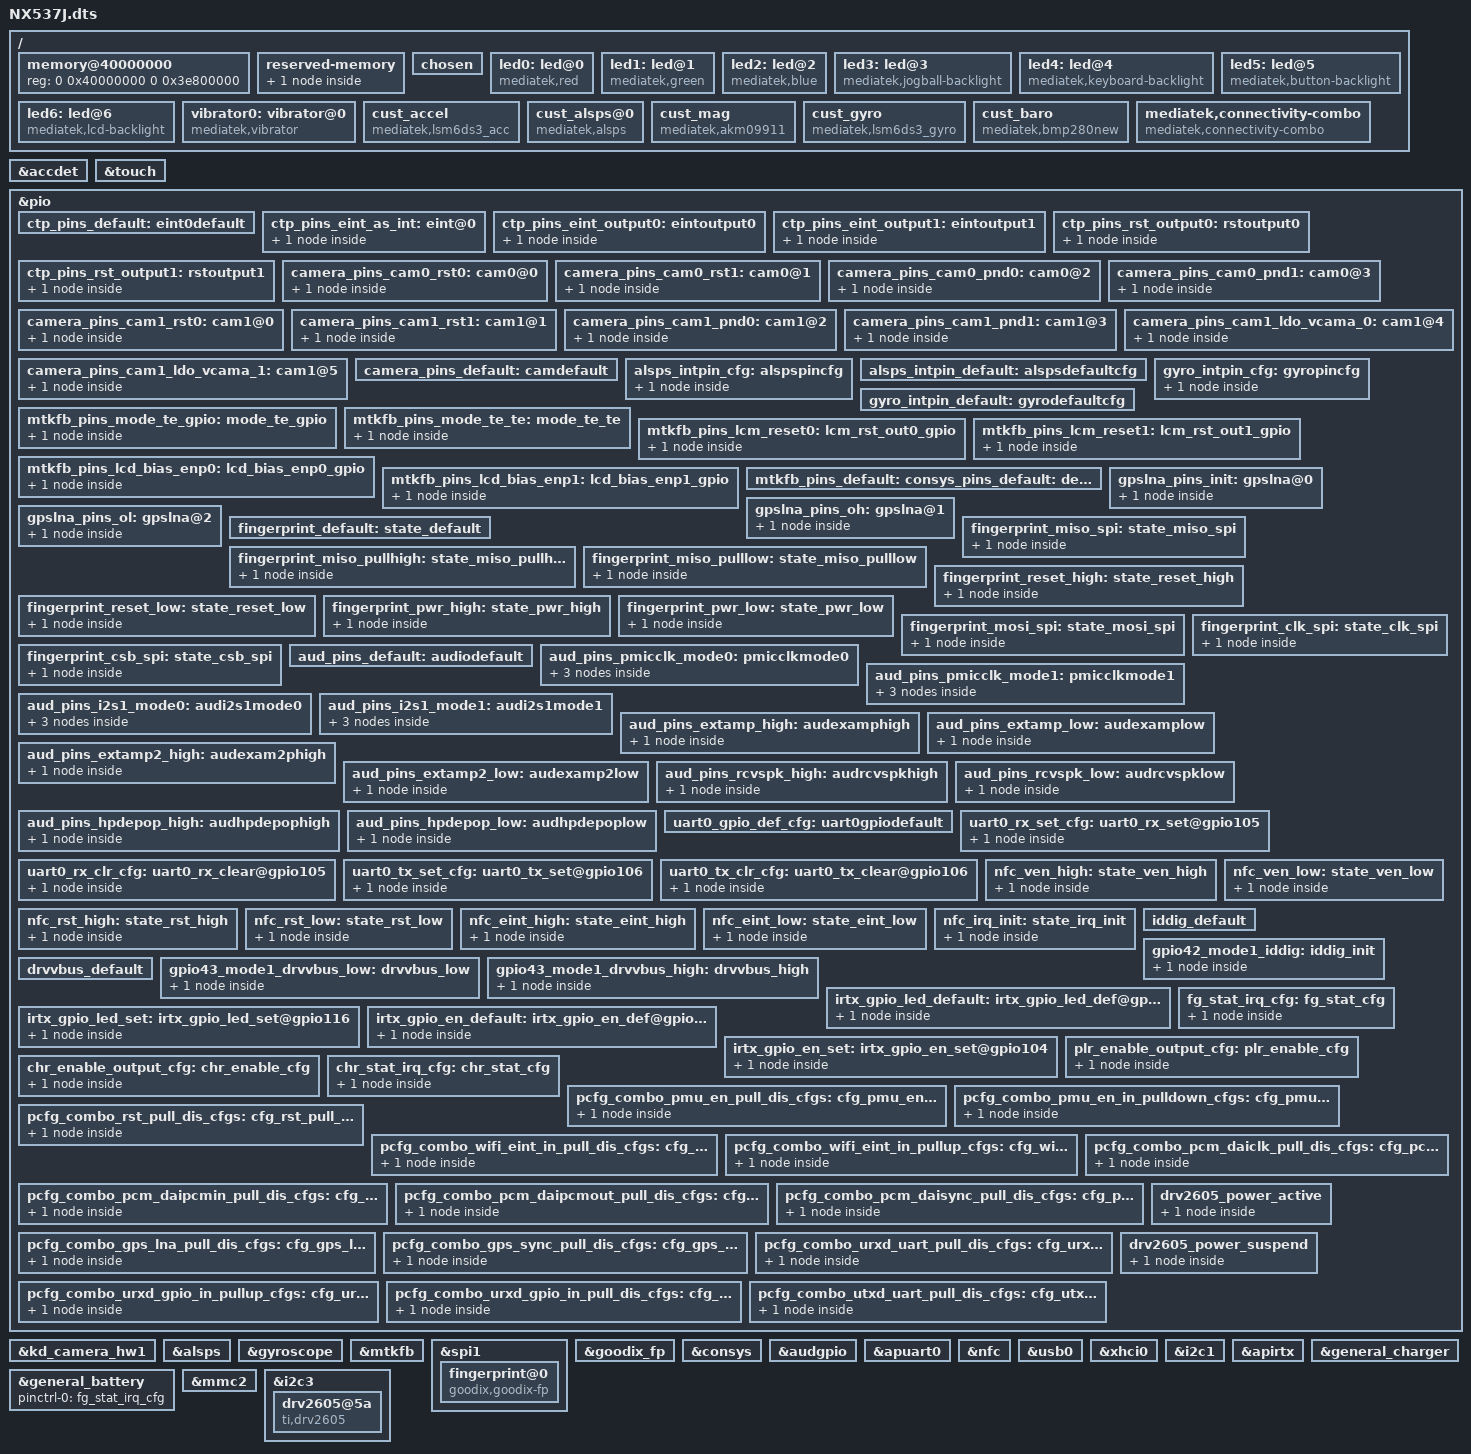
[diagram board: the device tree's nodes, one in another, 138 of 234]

/dts-v1/;

#include "mt6755_NX537J.dtsi"
#include "cust.dtsi"

/ {
	memory@40000000 {
		device_type = "memory";
		reg = <0 0x40000000 0 0x3e800000>;
	};
	reserved-memory {
		#address-cells = <2>;
		#size-cells = <2>;
		ranges;

		reserve-memory-ccci_md3_ccif {
			compatible = "mediatek,reserve-memory-ccci_md3_ccif";
			no-map;
			size = <0 0x01000000>;
			alignment = <0 0x2000000>;
			alloc-ranges = <0 0x40000000 0 0xc0000000>;
		};
	};

	/* chosen */
	chosen {
		bootargs = "console=tty0 console=ttyMT0,921600n1 root=/dev/ram initrd=0x44000000,0x4B434E loglevel=8";

		/* fpga may has no lk, we need to specify display info here */
		/* fb buffer is reserved using this dts by memory node above */
		atag,videolfb-fb_base_h = <0x0>;
		atag,videolfb-fb_base_l = <0x7E800000>;
		atag,videolfb-islcmfound = <1>;
		/* because no lk, so lcm is not inited */
		atag,videolfb-islcm_inited = <0>;
		atag,videolfb-fps= <6000>;
		atag,videolfb-vramSize= <0x01800000>;
		atag,videolfb-lcmname= "nt35695_fhd_dsi_cmd_truly_nt50358_drv";
	};
	led0:led@0 {
		compatible = "mediatek,red";
		led_mode = <0>;
		data = <1>;
		pwm_config = <0 0 0 0 0>;
	};
	led1:led@1 {
		compatible = "mediatek,green";
		led_mode = <0>;
		data = <1>;
		pwm_config = <0 0 0 0 0>;
	};
	led2:led@2 {
		compatible = "mediatek,blue";
		led_mode = <0>;
		data = <1>;
		pwm_config = <0 0 0 0 0>;
	};
	led3:led@3 {
		compatible = "mediatek,jogball-backlight";
		led_mode = <0>;
		data = <1>;
		pwm_config = <0 0 0 0 0>;
	};
	led4:led@4 {
		compatible = "mediatek,keyboard-backlight";
		led_mode = <0>;
		data = <1>;
		pwm_config = <0 0 0 0 0>;
	};
	led5:led@5 {
		compatible = "mediatek,button-backlight";
		led_mode = <0>;
		data = <1>;
		pwm_config = <0 0 0 0 0>;
	};
	led6:led@6 {
		compatible = "mediatek,lcd-backlight";
		led_mode = <4>;
		data = <1>;
		pwm_config = <0 0 0 0 0>;
	};
	vibrator0:vibrator@0 {
		compatible = "mediatek,vibrator";
		vib_timer = <25>;
		vib_limit = <9>;
		vib_vol= <5>;
	};
/*  start sensor */
	cust_accel {
		compatible = "mediatek,lsm6ds3_acc";
		i2c_num	= <1>;
		/* i2c_addr = <0x4c 0 0 0>; */
		direction = <0>;
		power_id = <0xffff>;
		power_vol = <0>;
		firlen = <16>;
		is_batch_supported = <1>;
	};

	cust_alsps@0 {
		compatible		= "mediatek,alsps";
		i2c_num			= <1>;
		i2c_addr		= <0x38 0 0 0>;
		polling_mode_ps		= <0>;
		polling_mode_als	= <1>;
		power_id		= <0xffff>;
		power_vol		= <0>;
/* Total has 15 level*/
		als_level	= <0 419 952 1557 3673 9092 9177 15211 26458 32570 38895 53287 65535 65535 65535>;
/*  Total has 16 range*/
		als_value	= <0 133 303 503 1003 2004 3008 5001 8009 10000 12000 16000 20000 20000 20000 20000>;
		ps_threshold_high	=  <32>;
		ps_threshold_low	=  <22>;
		is_batch_supported_ps	= <0>;
		is_batch_supported_als	= <0>;
	};

	cust_mag {
		compatible			= "mediatek,akm09911";
		i2c_num				= <1>;
		/* i2c_addr			= <0x0d 0 0 0>; */
		direction			= <1>;
		power_id			= <0xffff>;
		power_vol			= <0>;
		/* is_batch_supported		= <0>; */
	};

	cust_gyro {
		compatible			= "mediatek,lsm6ds3_gyro";
		i2c_num				= <1>;
		/* i2c_addr			= <0x68 0 0 0>; */
		direction			= <0>;
		power_id			= <0xffff>;
		power_vol			= <0>;
		firlen				= <0>;
		is_batch_supported		= <0>;
		addr                = <0x6b>;
	};

	cust_baro {
		compatible			= "mediatek,bmp280new";
		i2c_num				= <1>;
		/* i2c_addr			= <0x68 0 0 0>; */
		direction			= <0>;
		power_id			= <0xffff>;
		power_vol			= <0>;
		firlen				= <32>;
		is_batch_supported		= <0>;
	};
/* end sensor */

	mediatek,connectivity-combo {
		compatible = "mediatek,connectivity-combo";
		/*gpio_combo_ldo_en_pin = <&pio 0xffff 0>;	/*0) GPIO_COMBO_LDO_EN_PIN */
		/*gpio_combo_pmuv28_en_pin = <&pio 0xffff 0>;	/* 1) GPIO_COMBO_PMUV28_EN_PIN */
		gpio_combo_pmu_en_pin = <&pio 122 0>;		/* 2) GPIO_COMBO_PMU_EN_PIN */
		gpio_combo_rst_pin = <&pio 119 0>;		/* 3) GPIO_COMBO_RST_PIN pin */
		/*gpio_combo_bgf_eint_pin = <&pio 0xffff 0>;	/* 4) GPIO_COMBO_BGF_EINT_PIN */
		gpio_wifi_eint_pin = <&pio 120 0>;		/* 5) GPIO_WIFI_EINT_PIN */
		/*gpio_all_eint_pin = <&pio 0xffff 0>;		/* 6) GPIO_ALL_EINT_PIN */
		/*gpio_combo_urxd_pin = <&pio 0xffff 0>;		/* 7) GPIO_COMBO_URXD_PIN */
		/*gpio_combo_utxd_pin = <&pio 0xffff 0>;		/* 8) GPIO_COMBO_UTXD_PIN */
		gpio_pcm_daiclk_pin = <&pio 14 0>;		/* 9) GPIO_PCM_DAICLK_PIN */
		gpio_pcm_daipcmin_pin = <&pio 16 0>;		/* 10) GPIO_PCM_DAIPCMIN_PIN */
		gpio_pcm_daipcmout_pin = <&pio 15 0>;		/* 11) GPIO_PCM_DAIPCMOUT_PIN */
		gpio_pcm_daisync_pin = <&pio 13 0>;		/* 12) GPIO_PCM_DAISYNC_PIN */
		/*gpio_combo_i2s_ck_pin = <&pio 0xffff 0>;	/* 13) GPIO_COMBO_I2S_CK_PIN */
		/*gpio_combo_i2s_ws_pin = <&pio 0xffff 0>;	/* 14) GPIO_COMBO_I2S_WS_PIN */
		/*gpio_combo_i2s_dat_pin = <&pio 0xffff 0>;	/* 15) GPIO_COMBO_I2S_DAT_PIN */
		gpio_gps_sync_pin = <&pio 121 0>;		/* 16) GPIO_GPS_SYNC_PIN */
		gpio_gps_lna_pin = <&pio 114 0>;		/* 17) GPIO_GPS_LNA_PIN is ext pin on 6397 */
		gpio_combo_urxd_pin = <&pio 118 0>;
		gpio_combo_utxd_pin = <&pio 117 0>;
		pinctrl-names = "gpio_pmu_en_pull_dis",
			"gpio_pmu_en_in_pulldown",
			"gpio_rst_pull_dis",
			"gpio_wifi_eint_in_pull_dis",
			"gpio_wifi_eint_in_pullup",
			"gpio_pcm_daiclk_pull_dis",
			"gpio_pcm_daipcmin_pull_dis",
			"gpio_pcm_daipcmout_pull_dis",
			"gpio_pcm_daisync_pull_dis",
			"gpio_gps_lna_pull_dis",
			"gpio_gps_sync_pull_dis",
			"gpio_urxd_uart_pull_dis",
			"gpio_urxd_gpio_in_pullup",
			"gpio_urxd_gpio_in_pull_dis",
			"gpio_utxd_uart_pull_dis";
		pinctrl-0 = <&pcfg_combo_pmu_en_pull_dis_cfgs>;
		pinctrl-1 = <&pcfg_combo_pmu_en_in_pulldown_cfgs>;
		pinctrl-2 = <&pcfg_combo_rst_pull_dis_cfgs>;
		pinctrl-3 = <&pcfg_combo_wifi_eint_in_pull_dis_cfgs>;
		pinctrl-4 = <&pcfg_combo_wifi_eint_in_pullup_cfgs>;
		pinctrl-5 = <&pcfg_combo_pcm_daiclk_pull_dis_cfgs>;
		pinctrl-6 = <&pcfg_combo_pcm_daipcmin_pull_dis_cfgs>;
		pinctrl-7 = <&pcfg_combo_pcm_daipcmout_pull_dis_cfgs>;
		pinctrl-8 = <&pcfg_combo_pcm_daisync_pull_dis_cfgs>;
		pinctrl-9 = <&pcfg_combo_gps_lna_pull_dis_cfgs>;
		pinctrl-10 = <&pcfg_combo_gps_sync_pull_dis_cfgs>;
		pinctrl-11 = <&pcfg_combo_urxd_uart_pull_dis_cfgs>;
		pinctrl-12 = <&pcfg_combo_urxd_gpio_in_pullup_cfgs>;
		pinctrl-13 = <&pcfg_combo_urxd_gpio_in_pull_dis_cfgs>;
		pinctrl-14 = <&pcfg_combo_utxd_uart_pull_dis_cfgs>;
		interrupt-parent = <&eintc>;
		interrupts = < 120 IRQ_TYPE_LEVEL_LOW >;	/* WIFI EINT num is 1 active low level-sensitive */
		debounce = <18 0>;
		status = "okay";
	};
};
&accdet {
		accdet-mic-vol = <7>;
		headset-mode-setting = <0x500 0x500 1 0x3F0 0x800 0x800 0x200>;
		accdet-plugout-debounce = <20>;
		/*1:ACC mode, 2:low cost without in bias, 6:low cost with in bias*/
		accdet-mic-mode = <2>;
		/*0--MD_MAX--UP_MAX--DW_MAX*/
		headset-three-key-threshold = <0 80 220 500>;
		/*0--MD_MAX--VOICE_MAX--UP_MAX--DW_MAX*/
		headset-four-key-threshold = <0 58 121 192 450>;
};

/* TOUCH start */
&touch {
	tpd-resolution = <1080 1920>;
	use-tpd-button = <0>;
	tpd-key-num = <3>;
	tpd-key-local= <139 172 158 0>;
	tpd-key-dim-local = <90 883 100 40 230 883 100 40 370 883 100 40 0 0 0 0>;
	tpd-max-touch-num = <5>;
	tpd-filter-enable = <1>;
	tpd-filter-pixel-density = <146>;
	tpd-filter-custom-prameters = <0 0 0 0 0 0 0 0 0 0 0 0>;
	tpd-filter-custom-speed = <0 0 0>;
	pinctrl-names = "default", "state_eint_as_int", "state_eint_output0", "state_eint_output1",
		"state_rst_output0", "state_rst_output1";
	pinctrl-0 = <&ctp_pins_default>;
	pinctrl-1 = <&ctp_pins_eint_as_int>;
	pinctrl-2 = <&ctp_pins_eint_output0>;
	pinctrl-3 = <&ctp_pins_eint_output1>;
	pinctrl-4 = <&ctp_pins_rst_output0>;
	pinctrl-5 = <&ctp_pins_rst_output1>;
	status = "okay";
};
&pio {
	ctp_pins_default: eint0default {
	};
	ctp_pins_eint_as_int: eint@0 {
		pins_cmd_dat {
			pins = <PINMUX_GPIO5__FUNC_GPIO5>;
			slew-rate = <0>;
			bias-pull-up = <00>;
		};
	};
	ctp_pins_eint_output0: eintoutput0 {
		pins_cmd_dat {
			pins = <PINMUX_GPIO5__FUNC_GPIO5>;
			slew-rate = <1>;
			output-low;
		};
	};
	ctp_pins_eint_output1: eintoutput1 {
		pins_cmd_dat {
			pins = <PINMUX_GPIO5__FUNC_GPIO5>;
			slew-rate = <1>;
			output-high;
		};
	};
	ctp_pins_rst_output0: rstoutput0 {
		pins_cmd_dat {
			pins = <PINMUX_GPIO56__FUNC_GPIO56>;
			slew-rate = <1>;
			output-low;
		};
	};
	ctp_pins_rst_output1: rstoutput1 {
		pins_cmd_dat {
			pins = <PINMUX_GPIO56__FUNC_GPIO56>;
			slew-rate = <1>;
			output-high;
		};
	};
};
/* TOUCH end */

/* CAMERA GPIO standardization */
&pio {
	camera_pins_cam0_rst0: cam0@0 {
	    pins_cmd_dat {
			pins = <PINMUX_GPIO110__FUNC_GPIO110>;
			slew-rate = <1>; /*direction 0:in, 1:out*/
			output-low;/*direction out used only. output_low or high*/
		};
	};
	camera_pins_cam0_rst1: cam0@1 {
	    pins_cmd_dat {
			pins = <PINMUX_GPIO110__FUNC_GPIO110>;
			slew-rate = <1>;
			output-high;
		};
	};
	camera_pins_cam0_pnd0: cam0@2 {
	    pins_cmd_dat {
			pins = <PINMUX_GPIO107__FUNC_GPIO107>;
			slew-rate = <1>;
			output-low;
		};
	};
	camera_pins_cam0_pnd1: cam0@3 {
	    pins_cmd_dat {
			pins = <PINMUX_GPIO107__FUNC_GPIO107>;
			slew-rate = <1>;
			output-high;
		};
	};
	camera_pins_cam1_rst0: cam1@0 {
	    pins_cmd_dat {
			pins = <PINMUX_GPIO111__FUNC_GPIO111>;
			slew-rate = <1>; /*direction 0:in, 1:out*/
			output-low;/*direction out used only. output_low or high*/
		};
	};
	camera_pins_cam1_rst1: cam1@1 {
	    pins_cmd_dat {
			pins = <PINMUX_GPIO111__FUNC_GPIO111>;
			slew-rate = <1>;
			output-high;
		};
	};
	camera_pins_cam1_pnd0: cam1@2 {
	    pins_cmd_dat {
			pins = <PINMUX_GPIO108__FUNC_GPIO108>;
			slew-rate = <1>;
			output-low;
		};
	};
	camera_pins_cam1_pnd1: cam1@3 {
	    pins_cmd_dat {
			pins = <PINMUX_GPIO108__FUNC_GPIO108>;
			slew-rate = <1>;
			output-high;
		};
	};
	camera_pins_cam1_ldo_vcama_0: cam1@4 {
		       pins_cmd_dat {
			pins = <PINMUX_GPIO24__FUNC_GPIO24>;
			slew-rate = <1>;
			output-low;
		};
	};
	camera_pins_cam1_ldo_vcama_1: cam1@5 {
		    pins_cmd_dat {
			pins = <PINMUX_GPIO24__FUNC_GPIO24>;
			slew-rate = <1>;
			output-high;
		};
	};
	camera_pins_default: camdefault {
	};

};

&kd_camera_hw1 {
	pinctrl-names = "default",
			"cam0_rst0", "cam0_rst1", "cam0_pnd0", "cam0_pnd1",
			"cam1_rst0", "cam1_rst1", "cam1_pnd0", "cam1_pnd1",
			/*"cam2_rst0", "cam2_rst1", "cam2_pnd0", "cam2_pnd1",*/
			"cam1_ldo_vcama_0", "cam1_ldo_vcama_1";
	pinctrl-0 = <&camera_pins_default>;
	pinctrl-1 = <&camera_pins_cam0_rst0>;
	pinctrl-2 = <&camera_pins_cam0_rst1>;
	pinctrl-3 = <&camera_pins_cam0_pnd0>;
	pinctrl-4 = <&camera_pins_cam0_pnd1>;
	pinctrl-5 = <&camera_pins_cam1_rst0>;
	pinctrl-6 = <&camera_pins_cam1_rst1>;
	pinctrl-7 = <&camera_pins_cam1_pnd0>;
	pinctrl-8 = <&camera_pins_cam1_pnd1>;
	/* for main2 */
	/*pinctrl-9 = <&camera_pins_cam2_rst0>;
	pinctrl-10 = <&camera_pins_cam2_rst1>;
	pinctrl-11 = <&camera_pins_cam2_pnd0>;
	pinctrl-12 = <&camera_pins_cam2_pnd1>;*/
	/* for ldo control by gpio */
	pinctrl-9 = <&camera_pins_cam1_ldo_vcama_0>;
	pinctrl-10 = <&camera_pins_cam1_ldo_vcama_1>;
	status = "okay";

};
/* CAMERA GPIO end */

&pio {
	alsps_intpin_cfg: alspspincfg {

		pins_cmd_dat {
			pins = <PINMUX_GPIO12__FUNC_GPIO12>;
			slew-rate = <0>;
			bias-pull-up = <00>;
		};
	};

	alsps_intpin_default: alspsdefaultcfg {

	};

	gyro_intpin_cfg: gyropincfg {

		pins_cmd_dat {
			pins = <PINMUX_GPIO4__FUNC_GPIO4>;
			slew-rate = <0>;
			bias-pull-down = <00>;
		};
	};

	gyro_intpin_default: gyrodefaultcfg {

	};
};

&alsps {
	pinctrl-names = "pin_default", "pin_cfg";
	pinctrl-0 = <&alsps_intpin_default>;
	pinctrl-1 = <&alsps_intpin_cfg>;
	status = "okay";
};

&gyroscope {
	pinctrl-names = "pin_default", "pin_cfg";
	pinctrl-0 = <&gyro_intpin_default>;
	pinctrl-1 = <&gyro_intpin_cfg>;
	status = "okay";
};

/* DISPSYS GPIO standardization */
&pio {

	mtkfb_pins_mode_te_gpio: mode_te_gpio {
		pins_cmd_dat {
			pins = <PINMUX_GPIO44__FUNC_GPIO44>;
		};
	};

	mtkfb_pins_mode_te_te: mode_te_te {
		pins_cmd_dat {
			pins = <PINMUX_GPIO44__FUNC_DSI_TE>;
		};
	};

	mtkfb_pins_lcm_reset0: lcm_rst_out0_gpio {
		pins_cmd_dat {
			pins = <PINMUX_GPIO158__FUNC_LCM_RST>;
			slew-rate = <1>;
			output-low;
		};
	};

	mtkfb_pins_lcm_reset1: lcm_rst_out1_gpio {
		pins_cmd_dat {
			pins = <PINMUX_GPIO158__FUNC_LCM_RST>;
			slew-rate = <1>;
			output-high;
		};
	};

	mtkfb_pins_lcd_bias_enp0: lcd_bias_enp0_gpio {
		pins_cmd_dat {
			pins = <PINMUX_GPIO12__FUNC_GPIO12>;
			slew-rate = <1>;
			output-low;
		};
	};

	mtkfb_pins_lcd_bias_enp1: lcd_bias_enp1_gpio {
		pins_cmd_dat {
			pins = <PINMUX_GPIO12__FUNC_GPIO12>;
			slew-rate = <1>;
			output-high;
		};
	};

	mtkfb_pins_default: default {
	};
};

&mtkfb {
	pinctrl-names = "default", "mode_te_gpio", "mode_te_te", "lcm_rst_out0_gpio",
	"lcm_rst_out1_gpio", "lcd_bias_enp0_gpio", "lcd_bias_enp1_gpio";
	pinctrl-0 = <&mtkfb_pins_default>;
	pinctrl-1 = <&mtkfb_pins_mode_te_gpio>;
	pinctrl-2 = <&mtkfb_pins_mode_te_te>;
	pinctrl-3 = <&mtkfb_pins_lcm_reset0>;
	pinctrl-4 = <&mtkfb_pins_lcm_reset1>;
	pinctrl-5 = <&mtkfb_pins_lcd_bias_enp0>;
	pinctrl-6 = <&mtkfb_pins_lcd_bias_enp1>;
	status = "okay";
};/* DISPSYS GPIO standardization end */

/* CONSYS GPIO standardization */
&pio {
	consys_pins_default: default {
	};

	gpslna_pins_init: gpslna@0 {
		pins_cmd_dat {
			pins = <PINMUX_GPIO114__FUNC_GPIO114>;
			slew-rate = <0>;
			bias-disable;
			output-low;
		};
	};

	gpslna_pins_oh: gpslna@1 {
		pins_cmd_dat {
			pins = <PINMUX_GPIO114__FUNC_GPIO114>;
			slew-rate = <1>;
			output-high;
		};
	};

	gpslna_pins_ol: gpslna@2 {
		pins_cmd_dat {
			pins = <PINMUX_GPIO114__FUNC_GPIO114>;
			slew-rate = <1>;
			output-low;
		};
	};
};

/* FINGERPRINT start */
&spi1 {
	#address-cells = <1>;
	#size-cells = <0>;

	fingerprint@0 {
		compatible = "goodix,goodix-fp";
		reg = <0>;
		spi-max-frequency = <8000000>;
		status = "okay";
	};
};

&goodix_fp {
	pinctrl-names = "default", "miso_spi", "miso_pullhigh", "miso_pulllow", "reset_high", "reset_low", "pwr_high", "pwr_low", "mosi_spi", "clk_spi", "csb_spi";
	pinctrl-0 = <&fingerprint_default>;
	pinctrl-1 = <&fingerprint_miso_spi>;
	pinctrl-2 = <&fingerprint_miso_pullhigh>;
	pinctrl-3 = <&fingerprint_miso_pulllow>;
	pinctrl-4 = <&fingerprint_reset_high>;
	pinctrl-5 = <&fingerprint_reset_low>;
	pinctrl-6 = <&fingerprint_pwr_high>;
	pinctrl-7 = <&fingerprint_pwr_low>;
	pinctrl-8 = <&fingerprint_mosi_spi>;
	pinctrl-9 = <&fingerprint_clk_spi>;
	pinctrl-10 = <&fingerprint_csb_spi>;

	status = "okay";
};
&pio {
	fingerprint_default: state_default {

	};

	fingerprint_miso_spi: state_miso_spi {
		pins_cmd_dat {
			pins = <PINMUX_GPIO25__FUNC_SPI1_A_MI>;
		};
	};

	fingerprint_miso_pullhigh: state_miso_pullhigh {
		pins_cmd_dat {
			pins = <PINMUX_GPIO25__FUNC_GPIO25>;
			slew-rate = <1>;
			output-high;
		};
	};
	fingerprint_miso_pulllow: state_miso_pulllow {
		pins_cmd_dat {
			pins = <PINMUX_GPIO25__FUNC_GPIO25>;
			slew-rate = <1>;
			output-low;
		};
	};

	fingerprint_reset_high: state_reset_high {
		pins_cmd_dat {
			pins = <PINMUX_GPIO61__FUNC_GPIO61>;
			slew-rate = <1>;
			output-high;
		};
	};

	fingerprint_reset_low: state_reset_low {
		pins_cmd_dat {
			pins = <PINMUX_GPIO61__FUNC_GPIO61>;
			slew-rate = <1>;
			output-low;
		};
	};

	fingerprint_pwr_high: state_pwr_high {
		pins_cmd_dat {
			pins = <PINMUX_GPIO60__FUNC_GPIO60>;
			slew-rate = <1>;
			output-high;
		};
	};

	fingerprint_pwr_low: state_pwr_low {
		pins_cmd_dat {
			pins = <PINMUX_GPIO60__FUNC_GPIO60>;
			slew-rate = <1>;
			output-low;
		};
	};

	fingerprint_mosi_spi: state_mosi_spi {
		pins_cmd_dat {
			pins = <PINMUX_GPIO27__FUNC_SPI1_A_MO>;
		};
	};

	fingerprint_clk_spi: state_clk_spi {
		pins_cmd_dat {
			pins = <PINMUX_GPIO28__FUNC_SPI1_A_CLK>;
		};
	};

	fingerprint_csb_spi: state_csb_spi {
		pins_cmd_dat {
			pins = <PINMUX_GPIO26__FUNC_SPI1_A_CSB>;
		};
	};
};
/* FINGERPRINT end */
&consys {
	pinctrl-names = "default", "gps_lna_state_init", "gps_lna_state_oh", "gps_lna_state_ol";
	pinctrl-0 = <&consys_pins_default>;
	pinctrl-1 = <&gpslna_pins_init>;
	pinctrl-2 = <&gpslna_pins_oh>;
	pinctrl-3 = <&gpslna_pins_ol>;
	status = "okay";
};
/* CONSYS end */

/* AUDIO GPIO standardization */
&audgpio {
	pinctrl-names = "default", "audpmicclk-mode0", "audpmicclk-mode1",
		"audi2s1-mode0", "audi2s1-mode1", "extamp-pullhigh", "extamp-pulllow",
		"extamp2-pullhigh", "extamp2-pulllow", "rcvspk-pullhigh",
		"rcvspk-pulllow","hpdepop-pullhigh","hpdepop-pulllow";
	pinctrl-0 = <&aud_pins_default>;
	pinctrl-1 = <&aud_pins_pmicclk_mode0>;
	pinctrl-2 = <&aud_pins_pmicclk_mode1>;
	pinctrl-3 = <&aud_pins_i2s1_mode0>;
	pinctrl-4 = <&aud_pins_i2s1_mode1>;
	pinctrl-5 = <&aud_pins_default>;
	pinctrl-6 = <&aud_pins_default>;
	pinctrl-7 = <&aud_pins_extamp2_high>;
	pinctrl-8 = <&aud_pins_extamp2_low>;
	pinctrl-9 = <&aud_pins_rcvspk_high>;
	pinctrl-10 = <&aud_pins_rcvspk_low>;
	pinctrl-11 = <&aud_pins_hpdepop_high>;
	pinctrl-12 = <&aud_pins_hpdepop_low>;
	status = "okay";
};

&pio {
	aud_pins_default: audiodefault {
	};

	aud_pins_pmicclk_mode0: pmicclkmode0 {
		pins_cmd0_dat {
			pins = <PINMUX_GPIO149__FUNC_GPIO149>;
		};
		pins_cmd1_dat {
			pins = <PINMUX_GPIO150__FUNC_GPIO150>;
			slew-rate = <0>;
			bias-pull-up = <00>;
		};
		pins_cmd2_dat {
			pins = <PINMUX_GPIO151__FUNC_GPIO151>;
		};
	};

	aud_pins_pmicclk_mode1: pmicclkmode1 {
		pins_cmd0_dat {
			pins = <PINMUX_GPIO149__FUNC_AUD_CLK_MOSI>;
		};
		pins_cmd1_dat {
			pins = <PINMUX_GPIO150__FUNC_AUD_DAT_MOSI>;
		};
		pins_cmd2_dat {
			pins = <PINMUX_GPIO151__FUNC_AUD_DAT_MISO>;
		};
	};

	aud_pins_i2s1_mode0: audi2s1mode0 {
		pins_cmd0_dat {
			pins = <PINMUX_GPIO7__FUNC_GPIO7>;
		};
		pins_cmd1_dat {
			pins = <PINMUX_GPIO6__FUNC_GPIO6>;
		};
		pins_cmd2_dat {
			pins = <PINMUX_GPIO5__FUNC_GPIO5>;
		};
	};

	aud_pins_i2s1_mode1: audi2s1mode1 {
		pins_cmd0_dat {
			pins = <PINMUX_GPIO7__FUNC_I2S0_DI>;
		};
		pins_cmd1_dat {
			pins = <PINMUX_GPIO6__FUNC_I2S0_LRCK>;
		};
		pins_cmd2_dat {
			pins = <PINMUX_GPIO5__FUNC_I2S0_BCK>;
		};
	};

	aud_pins_extamp_high: audexamphigh {
		pins_cmd_dat {
			pins = <PINMUX_GPIO157__FUNC_GPIO157>;
			slew-rate = <1>;
			output-high;
		};
	};

	aud_pins_extamp_low: audexamplow {
		pins_cmd_dat {
			pins = <PINMUX_GPIO157__FUNC_GPIO157>;
			slew-rate = <1>;
			output-low;
		};
	};

	aud_pins_extamp2_high: audexam2phigh {
		pins_cmd_dat {
			pins = <PINMUX_GPIO54__FUNC_GPIO54>;
			slew-rate = <1>;
			output-high;
		};
	};
	aud_pins_extamp2_low: audexamp2low {
		pins_cmd_dat {
			pins = <PINMUX_GPIO54__FUNC_GPIO54>;
			slew-rate = <1>;
			output-low;
		};
	};

	aud_pins_rcvspk_high: audrcvspkhigh {
		pins_cmd_dat {
			pins = <PINMUX_GPIO120__FUNC_GPIO120>;
			slew-rate = <1>;
			output-high;
		};
	};

	aud_pins_rcvspk_low: audrcvspklow {
		pins_cmd_dat {
			pins = <PINMUX_GPIO120__FUNC_GPIO120>;
			slew-rate = <1>;
			output-low;
		};
	};

	aud_pins_hpdepop_high: audhpdepophigh {
		pins_cmd_dat {
			pins = <PINMUX_GPIO24__FUNC_GPIO24>;
			slew-rate = <1>;
			output-high;
		};
	};

	aud_pins_hpdepop_low: audhpdepoplow {
		pins_cmd_dat {
			pins = <PINMUX_GPIO24__FUNC_GPIO24>;
			slew-rate = <1>;
			output-low;
		};
	};
};
/* AUDIO GPIO end */

/* UART GPIO */
&apuart0 {
	pinctrl-names = "uart0_gpio_default",
			"uart0_rx_set",
			"uart0_rx_clear",
			"uart0_tx_set",
			"uart0_tx_clear";
	pinctrl-0 = <&uart0_gpio_def_cfg>;
	pinctrl-1 = <&uart0_rx_set_cfg>;
	pinctrl-2 = <&uart0_rx_clr_cfg>;
	pinctrl-3 = <&uart0_tx_set_cfg>;
	pinctrl-4 = <&uart0_tx_clr_cfg>;
	status = "okay";
};

&pio {
	/* UART GPIO Settings - Start */
	/* UART0: rx set, rx clear, tx clear, tx clear*/
	uart0_gpio_def_cfg:uart0gpiodefault {

	};
	uart0_rx_set_cfg:uart0_rx_set@gpio105 {
		pins_cmd_dat {
			pins = <PINMUX_GPIO105__FUNC_URXD0>;
		};
	};
	uart0_rx_clr_cfg:uart0_rx_clear@gpio105  {
		pins_cmd_dat {
			pins = <PINMUX_GPIO105__FUNC_GPIO105>;
			slew-rate = <1>;
			output-high;
		};
	};
	uart0_tx_set_cfg:uart0_tx_set@gpio106  {
		pins_cmd_dat {
			pins = <PINMUX_GPIO106__FUNC_UTXD0>;
		};
	};
	uart0_tx_clr_cfg:uart0_tx_clear@gpio106  {
		pins_cmd_dat {
			pins = <PINMUX_GPIO106__FUNC_GPIO106>;
			slew-rate = <1>;
			output-high;
		};
	};
};/* UART GPIO end */

/* NFC GPIO standardization */
&pio {
	nfc_default: default {

	};

	nfc_ven_high: state_ven_high {
		pins_cmd_dat {
			pins = <PINMUX_GPIO28__FUNC_GPIO28>;
			slew-rate = <1>;
			output-high;
		};
	};

	nfc_ven_low: state_ven_low {
		pins_cmd_dat {
			pins = <PINMUX_GPIO28__FUNC_GPIO28>;
			slew-rate = <1>;
			output-low;
		};
	};

	nfc_rst_high: state_rst_high {
		pins_cmd_dat {
			pins = <PINMUX_GPIO25__FUNC_GPIO25>;
			slew-rate = <1>;
			output-high;
		};
	};

	nfc_rst_low: state_rst_low {
		pins_cmd_dat {
			pins = <PINMUX_GPIO25__FUNC_GPIO25>;
			slew-rate = <1>;
			output-low;
		};
	};

	nfc_eint_high: state_eint_high {
		pins_cmd_dat {
			pins = <PINMUX_GPIO27__FUNC_GPIO27>;
			slew-rate = <1>;
			output-high;
		};
	};

	nfc_eint_low: state_eint_low {
		pins_cmd_dat {
			pins = <PINMUX_GPIO27__FUNC_GPIO27>;
			slew-rate = <1>;
			output-low;
		};
	};

	nfc_irq_init: state_irq_init {
		pins_cmd_dat {
			pins = <PINMUX_GPIO26__FUNC_GPIO26>;
			slew-rate = <0>;
			bias-pull-down = <00>;
		};
	};
};

&nfc {
	pinctrl-names = "default", "ven_high", "ven_low", "rst_high", "rst_low", "eint_high", "eint_low", "irq_init";
	pinctrl-0 = <&nfc_default>;
	pinctrl-1 = <&nfc_ven_high>;
	pinctrl-2 = <&nfc_ven_low>;
	pinctrl-3 = <&nfc_rst_high>;
	pinctrl-4 = <&nfc_rst_low>;
	pinctrl-5 = <&nfc_eint_high>;
	pinctrl-6 = <&nfc_eint_low>;
	pinctrl-7 = <&nfc_irq_init>;
	status = "okay";
};
/* NFC end */

&pio {
	iddig_default: iddig_default {
	};

	gpio42_mode1_iddig: iddig_init {
		pins_cmd_dat {
			pins = <PINMUX_GPIO42__FUNC_IDDIG>;
			slew-rate = <0>;
			bias-pull-up = <00>;
		};
	};
};

&pio {
	drvvbus_default: drvvbus_default {
	};

	gpio43_mode1_drvvbus_low: drvvbus_low {
		pins_cmd_dat {
			pins = <PINMUX_GPIO43__FUNC_USB_DRVVBUS>;
			slew-rate = <1>;
			output-low;
		};
	};

	gpio43_mode1_drvvbus_high: drvvbus_high {
		pins_cmd_dat {
			pins = <PINMUX_GPIO43__FUNC_USB_DRVVBUS>;
			slew-rate = <1>;
			output-high;
		};
	};
};

&usb0 {
	pinctrl-names = "iddig_default", "iddig_init";
	pinctrl-0 = <&iddig_default>;
	pinctrl-1 = <&gpio42_mode1_iddig>;
	status = "okay";
};

&xhci0 {
	pinctrl-names = "drvvbus_default", "drvvbus_low", "drvvbus_high";
	pinctrl-0 = <&drvvbus_default>;
	pinctrl-1 = <&gpio43_mode1_drvvbus_low>;
	pinctrl-2 = <&gpio43_mode1_drvvbus_high>;
	status = "okay";
};

&i2c1 {
/*
	gyro@68 {
		compatible = "mediatek,gyro";
		reg = <0x69>;
		status = "okay";
	};

	gsensor@68 {
		compatible = "mediatek,gsensor";
		reg = <0x68>;
		status = "okay";
	};
*/
};
/* IRTX GPIO end */
&apirtx {
	pinctrl-names = "irtx_gpio_led_default",
			"irtx_gpio_led_set",
			"irtx_gpio_en_default",
			"irtx_gpio_en_set";

	pinctrl-0 = <&irtx_gpio_led_default>;
	pinctrl-1 = <&irtx_gpio_led_set>;
	pinctrl-2 = <&irtx_gpio_en_default>;
	pinctrl-3 = <&irtx_gpio_en_set>;
	status = "okay";
};
&pio {
	/* IRTX GPIO Settings -Start */
	/* default: GPIO0, output, high */
	irtx_gpio_led_default:irtx_gpio_led_def@gpio116 {
		pins_cmd_dat {
			pins = <PINMUX_GPIO116__FUNC_GPIO116>;
			slew-rate = <1>;
			bias-disable;
			output-low;
			input-schmitt-enable = <0>;
		};
	};

	irtx_gpio_led_set:irtx_gpio_led_set@gpio116 {
		pins_cmd_dat {
			pins = <PINMUX_GPIO116__FUNC_IRTX_OUT>;
			slew-rate = <1>;
			output-high;
		};
	};

	irtx_gpio_en_default:irtx_gpio_en_def@gpio104 {
		pins_cmd_dat {
			pins = <PINMUX_GPIO104__FUNC_GPIO104>;
			slew-rate = <1>;
			bias-disable;
			output-low;
			input-schmitt-enable = <0>;
		};
	};

	irtx_gpio_en_set:irtx_gpio_en_set@gpio104 {
		pins_cmd_dat {
			pins = <PINMUX_GPIO104__FUNC_GPIO104>;
			slew-rate = <1>;
			output-high;
		};
	};


}; /* IRTX GPIO Settings -End */

/* Charge Settings Begin*/
&pio {
	fg_stat_irq_cfg: fg_stat_cfg {
		pins_cmd_dat {
			pins = <PINMUX_GPIO7__FUNC_GPIO7>;
			slew-rate = <0>;
			bias-pull-up = <00>;
		};
	};

	plr_enable_output_cfg: plr_enable_cfg {
		pins_cmd_dat {
			pins = <PINMUX_GPIO84__FUNC_GPIO84>;
			slew-rate = <1>;
			output-low;
		};
	};

	chr_enable_output_cfg: chr_enable_cfg {
		pins_cmd_dat {
			pins = <PINMUX_GPIO100__FUNC_GPIO100>;
			slew-rate = <1>;
			output-low;
		};
	};

	chr_stat_irq_cfg: chr_stat_cfg {
		pins_cmd_dat {
			pins = <PINMUX_GPIO101__FUNC_GPIO101>;
			slew-rate = <0>;
			bias-pull-up = <00>;
		};
	};
};

&general_charger {
	usb_iddig_detect = <&pio 42 0>;
	pinctrl-names = "chr_stat_cfg", "chr_enable_cfg", "plr_enable_cfg";
	pinctrl-0 = <&chr_stat_irq_cfg>;
	pinctrl-1 = <&chr_enable_output_cfg>;
	pinctrl-2 = <&plr_enable_output_cfg>;
	status = "okay";
};

&general_battery {
	pinctrl-names = "fg_stat_cfg";
	pinctrl-0 = <&fg_stat_irq_cfg>;
	status = "okay";
};
/* Charge Settings End*/

/* Connectivity GPIO standardization */
&pio {
	pcfg_combo_pmu_en_pull_dis_cfgs:cfg_pmu_en_pull_dis {
		combo_pins {
			pins = <PINMUX_GPIO122__FUNC_GPIO122>;
			bias-disable;
		};
	};

	pcfg_combo_pmu_en_in_pulldown_cfgs:cfg_pmu_en_in_pulldown {
		combo_pins {
			pins = <PINMUX_GPIO122__FUNC_GPIO122>;
			bias-pull-down;
		};
	};

	pcfg_combo_rst_pull_dis_cfgs:cfg_rst_pull_dis {
		combo_pins {
			pins = <PINMUX_GPIO119__FUNC_GPIO119>;
			bias-disable;
		};
	};

	pcfg_combo_wifi_eint_in_pull_dis_cfgs:cfg_wifi_eint_in_pull_dis {
		combo_pins {
			pins = <PINMUX_GPIO120__FUNC_GPIO120>;
			slew-rate = <0>;
			bias-disable;
		};
	};
	pcfg_combo_wifi_eint_in_pullup_cfgs:cfg_wifi_eint_in_pullup {
		combo_pins {
			pins = <PINMUX_GPIO120__FUNC_GPIO120>;
			slew-rate = <0>;
			bias-pull-up = <00>;
		};
	};

	pcfg_combo_pcm_daiclk_pull_dis_cfgs:cfg_pcm_daiclk_pull_dis {
		combo_pins {
			pins = <PINMUX_GPIO14__FUNC_MRG_CLK>;
			bias-disable;
		};
	};

	pcfg_combo_pcm_daipcmin_pull_dis_cfgs:cfg_pcm_daipcmin_pull_dis {
		combo_pins {
			pins = <PINMUX_GPIO16__FUNC_MRG_DI>;
			bias-disable;
		};
	};

	pcfg_combo_pcm_daipcmout_pull_dis_cfgs:cfg_pcm_daipcmout_pull_dis {
		combo_pins {
			pins = <PINMUX_GPIO15__FUNC_MRG_DO>;
			bias-disable;
		};
	};

	pcfg_combo_pcm_daisync_pull_dis_cfgs:cfg_pcm_daisync_pull_dis {
		combo_pins {
			pins = <PINMUX_GPIO13__FUNC_MRG_SYNC>;
			bias-disable;
		};
	};

	pcfg_combo_gps_lna_pull_dis_cfgs:cfg_gps_lna_pull_dis {
		combo_pins {
			pins = <PINMUX_GPIO114__FUNC_GPIO114>;
			bias-disable;
		};
	};

	pcfg_combo_gps_sync_pull_dis_cfgs:cfg_gps_sync_pull_dis {
		combo_pins {
			pins = <PINMUX_GPIO121__FUNC_AGPS_SYNC>;
			bias-disable;
		};
	};

	pcfg_combo_urxd_uart_pull_dis_cfgs:cfg_urxd_pull_dis {
		combo_pins {
		  pins = <PINMUX_GPIO118__FUNC_C2K_URXD1>;
		  bias-disable;
		};
	};

	pcfg_combo_urxd_gpio_in_pullup_cfgs:cfg_urxd_in_pullup {
		combo_pins {
			pins = <PINMUX_GPIO118__FUNC_C2K_URXD1>;
			input-enable;
			bias-pull-up;
		};
	};

	pcfg_combo_urxd_gpio_in_pull_dis_cfgs:cfg_urxd_in_pull_dis {
		combo_pins {
			pins = <PINMUX_GPIO118__FUNC_C2K_URXD1>;
			input-enable;
			bias-disable;
		};
	};
	pcfg_combo_utxd_uart_pull_dis_cfgs:cfg_utxd_pull_dis {
		combo_pins {
			pins = <PINMUX_GPIO117__FUNC_C2K_UTXD1>;
			bias-disable;
		};
	};

};
/* Connectivity end */

&mmc2 {
		status = "okay";
};

&i2c3 {
	drv2605@5a {
		compatible = "ti,drv2605";
		reg = <0x5a>;
		enable-gpio = <&pio 115 0>;
		pinctrl-names = "drv2605_power_active", "drv2605_power_suspend";
		pinctrl-0 = <&drv2605_power_active>;
		pinctrl-1 = <&drv2605_power_suspend>;
		status = "okay";
	};
};

&pio {
	drv2605_power_active: drv2605_power_active {
		pins_cmd_dat {
			pins = <PINMUX_GPIO115__FUNC_GPIO115>;
			slew-rate = <1>;
			output-high;
		};
	};

	drv2605_power_suspend: drv2605_power_suspend {
		pins_cmd_dat {
			pins = <PINMUX_GPIO115__FUNC_GPIO115>;
			slew-rate = <1>;
			output-low;
		};
	};
};
